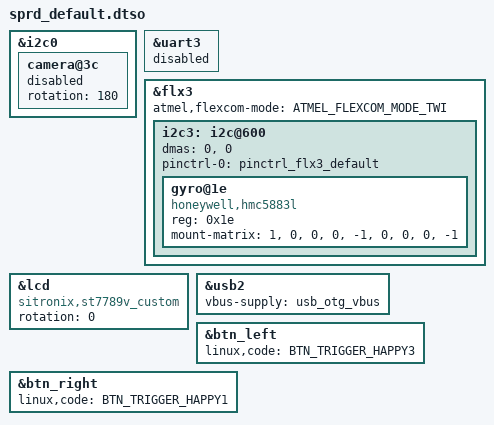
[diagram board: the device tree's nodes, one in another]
// SPDX-License-Identifier: (GPL-2.0+ OR MIT)
/*
 * sam9x60_curiosity_wilc3000.dtso - Device Tree file for SAM9x60-CURIOSITY board
 * overlay blob for ATWILC3000 - Wireless Modules.
 *
 * Copyright (C) 2022 Microchip Technology, Inc. and its subsidiaries
 * Author: Durai Manickam KR <durai.manickamkr@microchip.com>
 *
 */
/dts-v1/;
/plugin/;

#include <dt-bindings/input/input.h>
#include <dt-bindings/mfd/atmel-flexcom.h>

&i2c0 {
	camera@3c {
		rotation = <180>;
		status = "disabled";
	};
};

&uart3 {
	status = "disabled";
};

&flx3 {
	atmel,flexcom-mode = <ATMEL_FLEXCOM_MODE_TWI>;
	status = "okay";

	i2c3: i2c@600 {
		#address-cells = <1>;
		#size-cells = <0>;
		dmas = <0>, <0>;
		pinctrl-names = "default";
		pinctrl-0 = <&pinctrl_flx3_default>;
		status = "okay";

		gyro@1e {
			compatible = "honeywell,hmc5883l";
			reg = <0x1e>;
			mount-matrix = "1", "0", "0","0", "-1", "0", "0", "0", "-1";
			status = "okay";
		};

	};
};

&lcd {
	compatible = "sitronix,st7789v_custom";
	rotation = <0>;
};

&usb2 {
	vbus-supply = <&usb_otg_vbus>;
};

&btn_left {
	linux,code = <BTN_TRIGGER_HAPPY3>;
};

&btn_right {
	linux,code = <BTN_TRIGGER_HAPPY1>;
};


